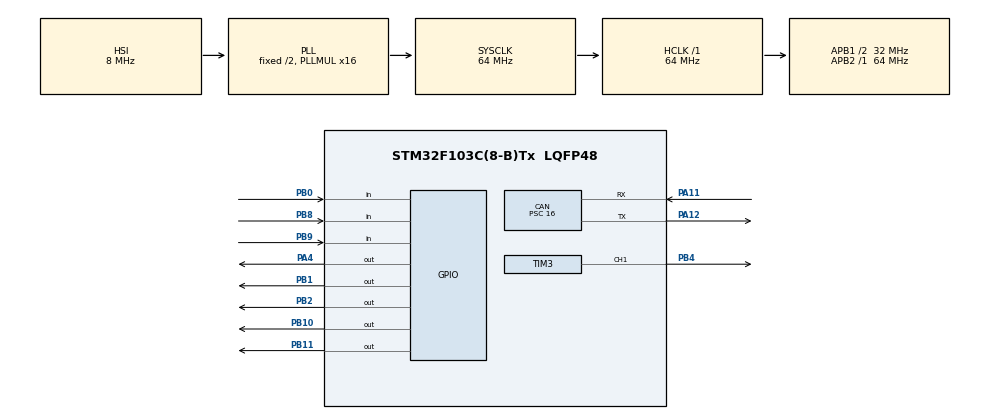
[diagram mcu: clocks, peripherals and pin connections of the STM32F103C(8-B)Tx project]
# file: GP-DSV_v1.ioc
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CAN.BS1=CAN_BS1_3TQ
CAN.BS2=CAN_BS2_4TQ
CAN.CalculateBaudRate=250000
CAN.CalculateTimeBit=4000
CAN.CalculateTimeQuantum=500.0
CAN.Prescaler=16
Mcu.Family=STM32F1
Mcu.Name=STM32F103C(8-B)Tx
Mcu.Package=LQFP48
NVIC.PriorityGroup=NVIC_PRIORITYGROUP_4
NVIC.USB_LP_CAN1_RX0_IRQn=true\:0\:0\:false\:false\:true\:true\:true
PA11.Mode=CAN_Activate
PA11.Signal=CAN_RX
PA12.Mode=CAN_Activate
PA12.Signal=CAN_TX
PA13.Mode=Serial_Wire
PA13.Signal=SYS_JTMS-SWDIO
PA14.Mode=Serial_Wire
PA14.Signal=SYS_JTCK-SWCLK
PA4.Signal=GPIO_Output
PB0.Signal=GPIO_Input
PB1.Signal=GPIO_Output
PB10.Signal=GPIO_Output
PB11.Signal=GPIO_Output
PB2.Signal=GPIO_Output
PB4.Signal=S_TIM3_CH1
PB8.Signal=GPIO_Input
PB9.Signal=GPIO_Input
ProjectManager.HeapSize=0x200
ProjectManager.StackSize=0x400
ProjectManager.TargetToolchain=STM32CubeIDE
RCC.AHBFreq_Value=64000000
RCC.APB1CLKDivider=RCC_HCLK_DIV2
RCC.APB1Freq_Value=32000000
RCC.APB1TimFreq_Value=64000000
RCC.APB2Freq_Value=64000000
RCC.APB2TimFreq_Value=64000000
RCC.HCLKFreq_Value=64000000
RCC.PLLMUL=RCC_PLL_MUL16
RCC.SYSCLKFreq_VALUE=64000000
RCC.SYSCLKSource=RCC_SYSCLKSOURCE_PLLCLK
RCC.USBFreq_Value=64000000
SH.S_TIM3_CH1.0=TIM3_CH1,PWM Generation1 CH1
TIM3.Channel-PWM\ Generation1\ CH1=TIM_CHANNEL_1
VP_TIM3_VS_ClockSourceINT.Mode=Internal
board=custom

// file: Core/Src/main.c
/* USER CODE BEGIN Header */
/**
  ******************************************************************************
  * @file           : main.c
  * @brief          : Main program body
  ******************************************************************************
  * @attention
  *
  * Copyright (c) 2022 STMicroelectronics.
  * All rights reserved.
  *
  * This software is licensed under terms that can be found in the LICENSE file
  * in the root directory of this software component.
  * If no LICENSE file comes with this software, it is provided AS-IS.
  *
  ******************************************************************************
  */
/* USER CODE END Header */
#include "main.h"
#include "can.h"
#include "tim.h"
#include "gpio.h"

/* USER CODE BEGIN Includes */
#include "genemek.h"
#include "gen_struct.h"
#include "gen_display.h"
/* USER CODE END Includes */

/* USER CODE BEGIN PTD */
gen_struct gen_s;
/* USER CODE END PTD */

void SystemClock_Config(void);

/* USER CODE BEGIN 0 */
 uint8_t can_rx_buffer[8] = {0,0,0,0,0,0,0,0};
	 uint8_t can_tx_buffer[8] = {0x00,0x01,0x02,0x03,0x04,0x05,0x06,0x07};
	CAN_TxHeaderTypeDef pTxHeader;
	CAN_RxHeaderTypeDef pRxHeader;
/* USER CODE END 0 */

int main(void)
{

  /* MCU Configuration--------------------------------------------------------*/

  /* Reset of all peripherals, Initializes the Flash interface and the Systick. */
  HAL_Init();

  /* Configure the system clock */
  SystemClock_Config();

  /* Initialize all configured peripherals */
  MX_GPIO_Init();
  MX_CAN_Init();
  MX_TIM3_Init();

  /* Infinite loop */
  while (1)
  {

    /* USER CODE BEGIN 3 */
	  gen_main();

  }
  /* USER CODE END 3 */
}

void SystemClock_Config(void)
{
  RCC_OscInitTypeDef RCC_OscInitStruct = {0};
  RCC_ClkInitTypeDef RCC_ClkInitStruct = {0};

  /** Initializes the RCC Oscillators according to the specified parameters
  * in the RCC_OscInitTypeDef structure.
  */
  RCC_OscInitStruct.OscillatorType = RCC_OSCILLATORTYPE_HSI;
  RCC_OscInitStruct.HSIState = RCC_HSI_ON;
  RCC_OscInitStruct.HSICalibrationValue = RCC_HSICALIBRATION_DEFAULT;
  RCC_OscInitStruct.PLL.PLLState = RCC_PLL_ON;
  RCC_OscInitStruct.PLL.PLLSource = RCC_PLLSOURCE_HSI_DIV2;
  RCC_OscInitStruct.PLL.PLLMUL = RCC_PLL_MUL16;
  if (HAL_RCC_OscConfig(&RCC_OscInitStruct) != HAL_OK)
  {
    Error_Handler();
  }
  /** Initializes the CPU, AHB and APB buses clocks
  */
  RCC_ClkInitStruct.ClockType = RCC_CLOCKTYPE_HCLK|RCC_CLOCKTYPE_SYSCLK
                              |RCC_CLOCKTYPE_PCLK1|RCC_CLOCKTYPE_PCLK2;
  RCC_ClkInitStruct.SYSCLKSource = RCC_SYSCLKSOURCE_PLLCLK;
  RCC_ClkInitStruct.AHBCLKDivider = RCC_SYSCLK_DIV1;
  RCC_ClkInitStruct.APB1CLKDivider = RCC_HCLK_DIV2;
  RCC_ClkInitStruct.APB2CLKDivider = RCC_HCLK_DIV1;

  if (HAL_RCC_ClockConfig(&RCC_ClkInitStruct, FLASH_LATENCY_2) != HAL_OK)
  {
    Error_Handler();
  }
}

/* USER CODE BEGIN 4 */
void HAL_CAN_RxFifo0MsgPendingCallback(CAN_HandleTypeDef *hcan)
	{

		HAL_CAN_GetRxMessage(hcan, CAN_RX_FIFO0, &pRxHeader, can_rx_buffer);

			  		   	  if(can_rx_buffer[5]==0x05)
			  		   	  {
			  		   		  gen_s.count2++;
			  		   		HAL_GPIO_TogglePin(GPIOA, GPIO_PIN_4);
	//		  		   		led_on();
			  		   	  }
			  		   		 // HAL_GPIO_WritePin(GPIOA, GPIO_PIN_4, GPIO_PIN_SET);
			  //	HAL_GPIO_TogglePin(GPIOA, GPIO_PIN_4);

	}

/* USER CODE END 4 */

void Error_Handler(void)
{
  __disable_irq();
  while (1)
  {
  }
}
